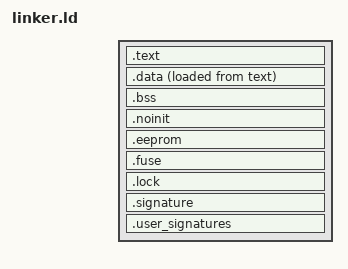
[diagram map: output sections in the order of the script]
/* Script for -n: mix text and data on same page */
/* Copyright (C) 2014-2015 Free Software Foundation, Inc.
   Copying and distribution of this script, with or without modification,
   are permitted in any medium without royalty provided the copyright
   notice and this notice are preserved.  */

OUTPUT_FORMAT("elf32-avr","elf32-avr","elf32-avr")
OUTPUT_ARCH(avr:5)

INCLUDE linker/memory.ld

SECTIONS
{
  .text   :
  {
    *(.bootloader_init)
    . = ALIGN(2);
    *(.text)
    . = ALIGN(2);
    *(.text.*)
    . = ALIGN(2);
     _etext = . ;
  }  > text
  .data          :
  {
     PROVIDE (__data_start = .) ;
    *(.data)
     *(.data*)
    *(.gnu.linkonce.d*)
    *(.rodata)  /* We need to include .rodata here if gcc is used */
     *(.rodata*) /* with -fdata-sections.  */
    *(.gnu.linkonce.r*)
    . = ALIGN(2);
     _edata = . ;
     PROVIDE (__data_end = .) ;
  }  > data AT> text
  .bss  ADDR(.data) + SIZEOF (.data)   : AT (ADDR (.bss))
  {
     PROVIDE (__bss_start = .) ;
    *(.bss)
     *(.bss*)
    *(COMMON)
     PROVIDE (__bss_end = .) ;
  }  > data
   __data_load_start = LOADADDR(.data);
   __data_load_end = __data_load_start + SIZEOF(.data);
  /* Global data not cleared after reset.  */
  .noinit  ADDR(.bss) + SIZEOF (.bss)  :  AT (ADDR (.noinit))
  {
     PROVIDE (__noinit_start = .) ;
    *(.noinit*)
     PROVIDE (__noinit_end = .) ;
     _end = . ;
     PROVIDE (__heap_start = .) ;
  }  > data
  .eeprom  :
  {
    /* See .data above...  */
    KEEP(*(.eeprom*))
     __eeprom_end = . ;
  }  > eeprom
  .fuse  :
  {
    KEEP(*(.fuse))
    KEEP(*(.lfuse))
    KEEP(*(.hfuse))
    KEEP(*(.efuse))
  }  > fuse
  .lock  :
  {
    KEEP(*(.lock*))
  }  > lock
  .signature  :
  {
    KEEP(*(.signature*))
  }  > signature
  .user_signatures  :
  {
    KEEP(*(.user_signatures*))
  }  > user_signatures
}
